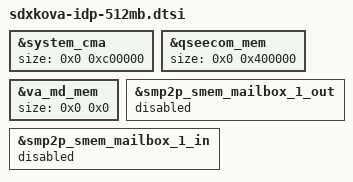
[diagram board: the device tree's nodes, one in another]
// SPDX-License-Identifier: BSD-3-Clause
/*
 * Copyright (c) Qualcomm Technologies, Inc. and/or its subsidiaries.
 */

/ {
};

&system_cma {
	size = <0x0 0xc00000>;
};

&qseecom_mem {
	size = <0x0 0x400000>;
};

&va_md_mem {
	size = <0x0 0x0>;
};

&smp2p_smem_mailbox_1_out {
	status = "disabled";
};

&smp2p_smem_mailbox_1_in {
	status = "disabled";
};
